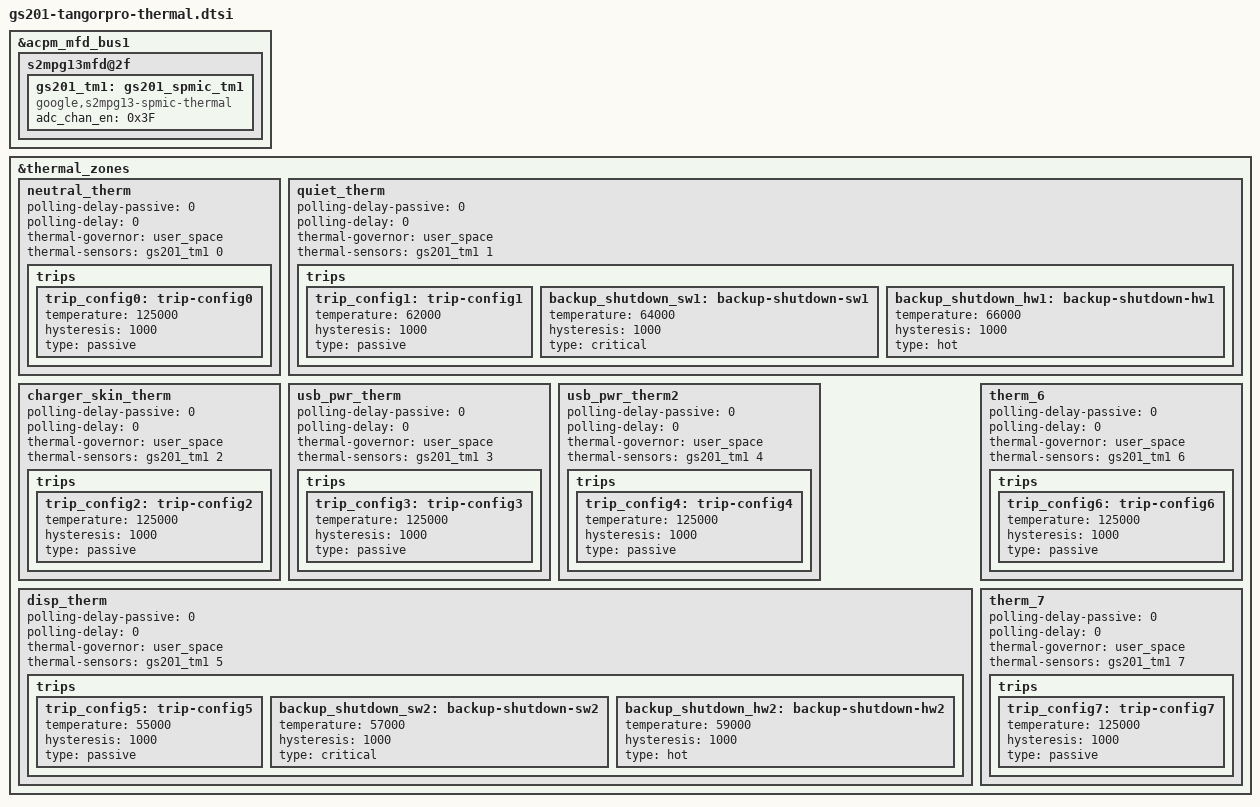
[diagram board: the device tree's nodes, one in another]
// SPDX-License-Identifier: GPL-2.0
/*
 * Google GS201 tangorpro-specific thermal device tree source
 *
 * Copyright (c) 2022 Google, LLC
 *		https://www.google.com
 */

#include <dt-bindings/thermal/thermal.h>

&acpm_mfd_bus1 {
	s2mpg13mfd@2f {
		gs201_tm1: gs201_spmic_tm1 {
			compatible = "google,s2mpg13-spmic-thermal";
			#thermal-sensor-cells = <1>;
			adc_chan_en = /bits/ 8 <0x3F>;
		};
	};
};

/* Thermal Zones */
&thermal_zones {
	neutral_therm {
		polling-delay-passive = <0>;
		polling-delay = <0>;
		thermal-governor = "user_space";
		thermal-sensors = <&gs201_tm1 0>;
		trips {
			trip_config0: trip-config0 {
				temperature = <125000>;
				hysteresis = <1000>;
				type = "passive";
			};
		};
	};
	quiet_therm {
		polling-delay-passive = <0>;
		polling-delay = <0>;
		thermal-governor = "user_space";
		thermal-sensors = <&gs201_tm1 1>;
		trips {
			trip_config1: trip-config1 {
				temperature = <62000>;
				hysteresis = <1000>;
				type = "passive";
			};
			backup_shutdown_sw1: backup-shutdown-sw1 {
				temperature = <64000>;
				hysteresis = <1000>;
				type = "critical";
			};
			backup_shutdown_hw1: backup-shutdown-hw1 {
				temperature = <66000>;
				hysteresis = <1000>;
				type = "hot";
			};
		};
	};
	charger_skin_therm {
		polling-delay-passive = <0>;
		polling-delay = <0>;
		thermal-governor = "user_space";
		thermal-sensors = <&gs201_tm1 2>;
		trips {
			trip_config2: trip-config2 {
				temperature = <125000>;
				hysteresis = <1000>;
				type = "passive";
			};
		};
	};
	usb_pwr_therm {
		polling-delay-passive = <0>;
		polling-delay = <0>;
		thermal-governor = "user_space";
		thermal-sensors = <&gs201_tm1 3>;
		trips {
			trip_config3: trip-config3 {
				temperature = <125000>;
				hysteresis = <1000>;
				type = "passive";
			};
		};
	};
	usb_pwr_therm2 {
		polling-delay-passive = <0>;
		polling-delay = <0>;
		thermal-governor = "user_space";
		thermal-sensors = <&gs201_tm1 4>;
		trips {
			trip_config4: trip-config4 {
				temperature = <125000>;
				hysteresis = <1000>;
				type = "passive";
			};
		};
	};
	disp_therm {
		polling-delay-passive = <0>;
		polling-delay = <0>;
		thermal-governor = "user_space";
		thermal-sensors = <&gs201_tm1 5>;
		trips {
			trip_config5: trip-config5 {
				temperature = <55000>;
				hysteresis = <1000>;
				type = "passive";
			};
			backup_shutdown_sw2: backup-shutdown-sw2 {
				temperature = <57000>;
				hysteresis = <1000>;
				type = "critical";
			};
			backup_shutdown_hw2: backup-shutdown-hw2 {
				temperature = <59000>;
				hysteresis = <1000>;
				type = "hot";
			};
		};
	};
	therm_6 {
		polling-delay-passive = <0>;
		polling-delay = <0>;
		thermal-governor = "user_space";
		thermal-sensors = <&gs201_tm1 6>;
		trips {
			trip_config6: trip-config6 {
				temperature = <125000>;
				hysteresis = <1000>;
				type = "passive";
			};
		};
	};
	therm_7 {
		polling-delay-passive = <0>;
		polling-delay = <0>;
		thermal-governor = "user_space";
		thermal-sensors = <&gs201_tm1 7>;
		trips {
			trip_config7: trip-config7 {
				temperature = <125000>;
				hysteresis = <1000>;
				type = "passive";
			};
		};
	};
};
